# asyncc register map
File version: 0.0
async runtime controller descript
Registers are 32-bit, read-write, reset 0x0 unless marked. A register's access mark holds for its fields unless they carry their own. Offsets are from the block's base; lines under a group give offsets from that group; [hi:lo] are bit positions; {n}, {i} and the like mark numbered series; 'fields as' and 'values as' point back to an identical list; <NAME> marks a mode.

## Memory map
0x60040000 ASYNCC size 0x10000 — Async Runtime Controller

## ASYNCC — Async Runtime Controller
Base 0x60040000
0x00 eptr — Executor Base Address register
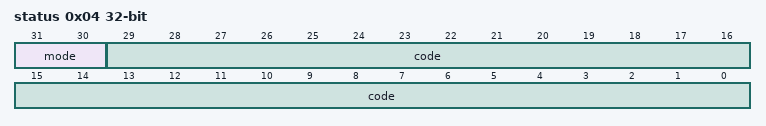
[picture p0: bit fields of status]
0x04 status — Execution Flow status register
  [31:30] mode — The mode of execution flow change
    3=interrupt; 2=exception; 1=Await; 0=finish
  [29:0] code — The code of cause
0x08 msgbuf — Message Buffer Base Address register
0x0C curc — Current coroutine register
{0x10+8i} a{i}_lsb (i=0..7) — Argument A{i} LSB
{0x14+8i} a{i}_msb (i=0..7) — Argument A{i} MSB
